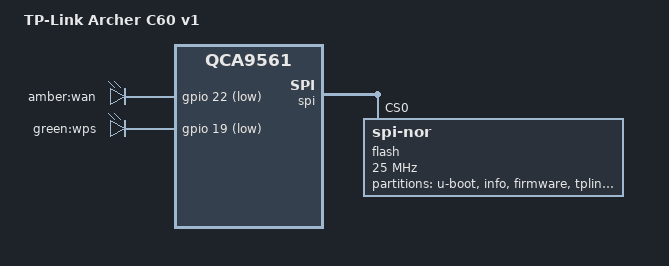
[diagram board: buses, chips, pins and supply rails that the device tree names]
// SPDX-License-Identifier: GPL-2.0-or-later OR MIT

#include "qca9561_tplink_archer-c6x.dtsi"

/ {
	compatible = "tplink,archer-c60-v1", "qca,qca9561";
	model = "TP-Link Archer C60 v1";
};

&leds {
	wan_amber {
		label = "amber:wan";
		gpios = <&gpio 22 GPIO_ACTIVE_LOW>;
	};

	wps {
		label = "green:wps";
		gpios = <&gpio 19 GPIO_ACTIVE_LOW>;
	};
};

&spi {
	status = "okay";

	flash@0 {
		compatible = "jedec,spi-nor";
		reg = <0>;
		spi-max-frequency = <25000000>;

		partitions {
			compatible = "fixed-partitions";
			#address-cells = <1>;
			#size-cells = <1>;

			partition@0 {
				label = "u-boot";
				reg = <0x000000 0x010000>;
				read-only;
			};

			info: partition@10000 {
				label = "info";
				reg = <0x010000 0x010000>;
				read-only;
			};

			partition@20000 {
				compatible = "denx,uimage";
				label = "firmware";
				reg = <0x020000 0x7c0000>;
			};

			partition@7e0000 {
				label = "tplink";
				reg = <0x7e0000 0x010000>;
				read-only;
			};

			art: partition@7f0000 {
				label = "art";
				reg = <0x7f0000 0x010000>;
				read-only;
			};
		};
	};
};
